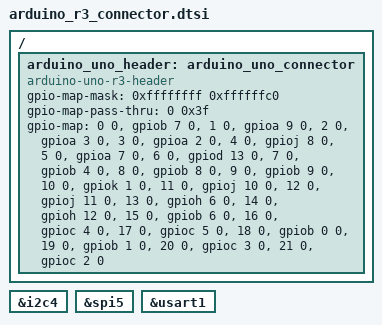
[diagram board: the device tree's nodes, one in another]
/*
 * Copyright 2023 Google LLC
 *
 * SPDX-License-Identifier: Apache-2.0
 */

/ {
	arduino_uno_header: arduino_uno_connector {
		compatible = "arduino-uno-r3-header";
		#gpio-cells = <2>;
		gpio-map-mask = <0xffffffff 0xffffffc0>;
		gpio-map-pass-thru = <0 0x3f>;
		gpio-map = < 0 0 &gpiob 7  0>,	/* D0 */
			   < 1 0 &gpioa 9  0>,	/* D1 */
			   < 2 0 &gpioa 3  0>,	/* D2 */
			   < 3 0 &gpioa 2  0>,	/* D3 */
			   < 4 0 &gpioj 8  0>,	/* D4 */
			   < 5 0 &gpioa 7  0>,	/* D5 */
			   < 6 0 &gpiod 13 0>,	/* D6 */
			   < 7 0 &gpiob 4  0>,	/* D7 */
			   < 8 0 &gpiob 8  0>,	/* D8 */
			   < 9 0 &gpiob 9  0>,	/* D9 */
			   <10 0 &gpiok 1  0>,	/* D10 */
			   <11 0 &gpioj 10 0>,	/* D11 */
			   <12 0 &gpioj 11 0>,	/* D12 */
			   <13 0 &gpioh 6  0>,	/* D13 */
			   <14 0 &gpioh 12 0>,	/* D14 */
			   <15 0 &gpiob 6  0>,	/* D15 */
			   <16 0 &gpioc 4  0>,	/* A0 */
			   <17 0 &gpioc 5  0>,	/* A1 */
			   <18 0 &gpiob 0  0>,	/* A2 */
			   <19 0 &gpiob 1  0>,	/* A3 */
			   <20 0 &gpioc 3  0>,	/* A4 */
			   <21 0 &gpioc 2  0>;	/* A5 */
	};
};

#include <arduino/arduino-header-r3-compat.dtsi>

arduino_i2c: &i2c4 {};
arduino_spi: &spi5 {};
arduino_serial: &usart1 {};
